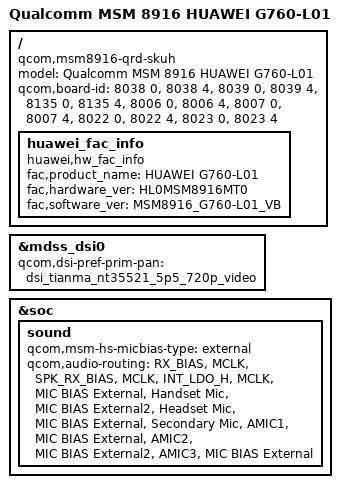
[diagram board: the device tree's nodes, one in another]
/* Copyright (c) 2014, The Linux Foundation. All rights reserved.
 * Copyright (c) 2016, @surdu_petru
 *
 * This program is free software; you can redistribute it and/or modify
 * it under the terms of the GNU General Public License version 2 and
 * only version 2 as published by the Free Software Foundation.
 *
 * This program is distributed in the hope that it will be useful,
 * but WITHOUT ANY WARRANTY; without even the implied warranty of
 * MERCHANTABILITY or FITNESS FOR A PARTICULAR PURPOSE.  See the
 * GNU General Public License for more details.
 */
/dts-v1/;

#include "msm8916-qrd.dtsi"
#include "msm8916-memory.dtsi"
#include "g760/huawei-g760.dtsi"

/ {
	model = "Qualcomm MSM 8916 HUAWEI G760-L01";
	compatible = "qcom,msm8916-qrd-skuh", "qcom,msm8916-qrd", "qcom,msm8916", "qcom,qrd";
	qcom,board-id = <8038 0>, <8038 4>, <8039 0>, <8039 4>, <8135 0>, <8135 4>, <8006 0>, <8006 4>,
			<8007 0>, <8007 4>, <8022 0>, <8022 4>, <8023 0>, <8023 4>;
};

&mdss_dsi0 {
	qcom,dsi-pref-prim-pan = <&dsi_tianma_nt35521_5p5_720p_video>;
};

&soc {

	sound {
		qcom,msm-hs-micbias-type = "external";
		qcom,audio-routing =
				"RX_BIAS", "MCLK",
				"SPK_RX_BIAS", "MCLK",
				"INT_LDO_H", "MCLK",
				"MIC BIAS External", "Handset Mic",
				"MIC BIAS External2", "Headset Mic",
				"MIC BIAS External", "Secondary Mic",
				"AMIC1", "MIC BIAS External",
				"AMIC2", "MIC BIAS External2",
				"AMIC3", "MIC BIAS External";
	};

};

/ {
        huawei_fac_info {
                  compatible = "huawei,hw_fac_info";
                  fac,product_name = "HUAWEI G760-L01";
                  fac,hardware_ver = "HL0MSM8916MT0";
                  fac,software_ver = "MSM8916_G760-L01_VB";
                  status = "ok";
        };
};

